# MSS_CTRL_MSS_CTRL register map
Vendor: Texas Instruments
Peripheral module from a debugger description file (folder AM263).
Registers are 32-bit, read-only, reset 0x0 unless marked. A register's access mark holds for its fields unless they carry their own. Offsets are as the file gives them; lines under a group give offsets from that group; [hi:lo] are bit positions; {n}, {i} and the like mark numbered series; 'fields as' and 'values as' point back to an identical list; <NAME> marks a mode.

## MSS_CTRL_MSS_CTRL (part 1 of 5)
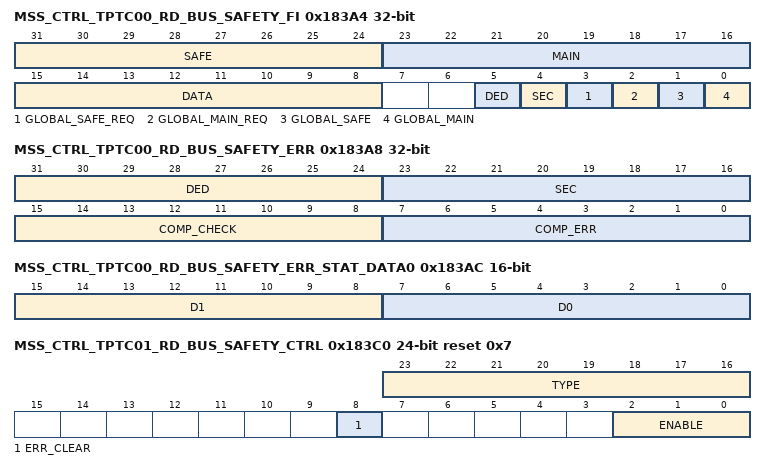
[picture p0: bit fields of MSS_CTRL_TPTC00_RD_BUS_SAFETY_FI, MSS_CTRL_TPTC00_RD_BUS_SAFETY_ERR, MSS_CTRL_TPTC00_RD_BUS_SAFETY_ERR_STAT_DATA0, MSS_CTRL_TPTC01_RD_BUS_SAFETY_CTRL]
0x183A4 MSS_CTRL_TPTC00_RD_BUS_SAFETY_FI rw
  [31:24] SAFE — Refer to AM602 Substem Microarch document for more details
  [23:16] MAIN — Refer to AM602 Substem Microarch document for more details
  [15:8] DATA — Refer to AM602 Substem Microarch document for more details
  [5] DED — Refer to AM602 Substem Microarch document for more details
  [4] SEC — Refer to AM602 Substem Microarch document for more details
  [3] GLOBAL_SAFE_REQ — Refer to AM602 Substem Microarch document for more details
  [2] GLOBAL_MAIN_REQ — Refer to AM602 Substem Microarch document for more details
  [1] GLOBAL_SAFE — Refer to AM602 Substem Microarch document for more details
  [0] GLOBAL_MAIN — Refer to AM602 Substem Microarch document for more details
0x183A8 MSS_CTRL_TPTC00_RD_BUS_SAFETY_ERR
  [31:24] DED — Refer to AM602 Substem Microarch document for more details
  [23:16] SEC — Refer to AM602 Substem Microarch document for more details
  [15:8] COMP_CHECK — Refer to AM602 Substem Microarch document for more details
  [7:0] COMP_ERR — Refer to AM602 Substem Microarch document for more details
0x183AC MSS_CTRL_TPTC00_RD_BUS_SAFETY_ERR_STAT_DATA0 16-bit
  [15:8] D1 — Refer to AM602 Substem Microarch document for more details
  [7:0] D0 — Refer to AM602 Substem Microarch document for more details
0x183B0 MSS_CTRL_TPTC00_RD_BUS_SAFETY_ERR_STAT_CMD
  [31:0] STAT — Refer to AM602 Substem Microarch document for more details
0x183B4 MSS_CTRL_TPTC00_RD_BUS_SAFETY_ERR_STAT_READ
  fields as MSS_CTRL_TPTC00_RD_BUS_SAFETY_ERR_STAT_CMD
0x183C0 MSS_CTRL_TPTC01_RD_BUS_SAFETY_CTRL 24-bit access per field reset 0x7
  [23:16] TYPE ro — Refer to AM602 Substem Microarch document for more details
  [8] ERR_CLEAR rw — Refer to AM602 Substem Microarch document for more details
  [2:0] ENABLE rw — Refer to AM602 Substem Microarch document for more details
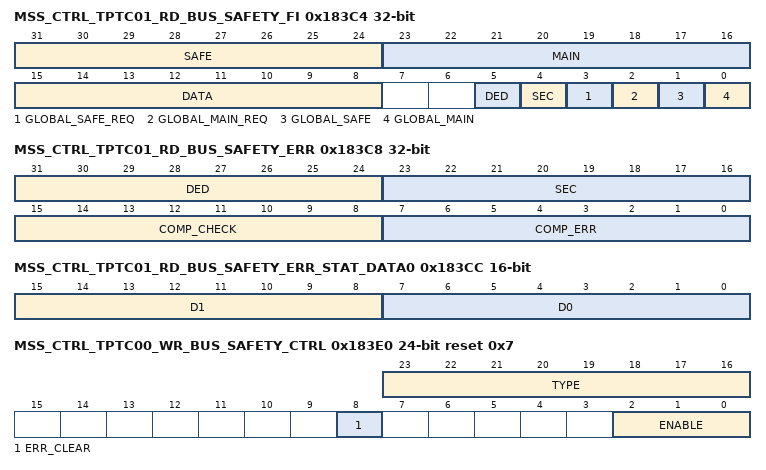
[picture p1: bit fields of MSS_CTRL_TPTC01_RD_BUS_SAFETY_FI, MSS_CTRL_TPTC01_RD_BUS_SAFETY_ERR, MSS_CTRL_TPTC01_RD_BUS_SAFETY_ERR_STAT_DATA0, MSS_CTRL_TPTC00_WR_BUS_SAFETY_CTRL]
0x183C4 MSS_CTRL_TPTC01_RD_BUS_SAFETY_FI rw
  fields as MSS_CTRL_TPTC00_RD_BUS_SAFETY_FI
0x183C8 MSS_CTRL_TPTC01_RD_BUS_SAFETY_ERR
  fields as MSS_CTRL_TPTC00_RD_BUS_SAFETY_ERR
0x183CC MSS_CTRL_TPTC01_RD_BUS_SAFETY_ERR_STAT_DATA0 16-bit
  fields as MSS_CTRL_TPTC00_RD_BUS_SAFETY_ERR_STAT_DATA0
0x183D0 MSS_CTRL_TPTC01_RD_BUS_SAFETY_ERR_STAT_CMD
  fields as MSS_CTRL_TPTC00_RD_BUS_SAFETY_ERR_STAT_CMD
0x183D4 MSS_CTRL_TPTC01_RD_BUS_SAFETY_ERR_STAT_READ
  fields as MSS_CTRL_TPTC00_RD_BUS_SAFETY_ERR_STAT_CMD
0x183E0 MSS_CTRL_TPTC00_WR_BUS_SAFETY_CTRL 24-bit access per field reset 0x7
  fields as MSS_CTRL_TPTC01_RD_BUS_SAFETY_CTRL
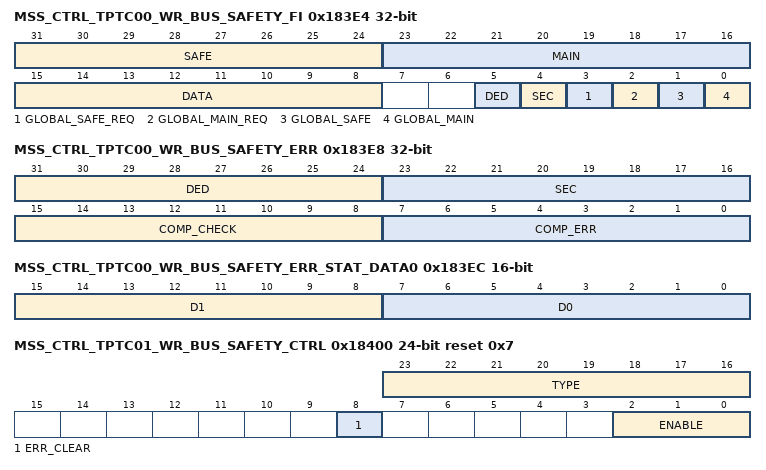
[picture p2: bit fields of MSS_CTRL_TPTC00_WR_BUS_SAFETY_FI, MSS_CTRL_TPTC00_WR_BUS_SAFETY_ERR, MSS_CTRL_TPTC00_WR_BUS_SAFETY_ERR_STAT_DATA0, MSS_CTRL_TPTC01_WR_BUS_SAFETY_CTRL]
0x183E4 MSS_CTRL_TPTC00_WR_BUS_SAFETY_FI rw
  fields as MSS_CTRL_TPTC00_RD_BUS_SAFETY_FI
0x183E8 MSS_CTRL_TPTC00_WR_BUS_SAFETY_ERR
  fields as MSS_CTRL_TPTC00_RD_BUS_SAFETY_ERR
0x183EC MSS_CTRL_TPTC00_WR_BUS_SAFETY_ERR_STAT_DATA0 16-bit
  fields as MSS_CTRL_TPTC00_RD_BUS_SAFETY_ERR_STAT_DATA0
0x183F0 MSS_CTRL_TPTC00_WR_BUS_SAFETY_ERR_STAT_CMD
  fields as MSS_CTRL_TPTC00_RD_BUS_SAFETY_ERR_STAT_CMD
0x183F4 MSS_CTRL_TPTC00_WR_BUS_SAFETY_ERR_STAT_WRITE
  fields as MSS_CTRL_TPTC00_RD_BUS_SAFETY_ERR_STAT_CMD
0x183F8 MSS_CTRL_TPTC00_WR_BUS_SAFETY_ERR_STAT_WRITERESP
  fields as MSS_CTRL_TPTC00_RD_BUS_SAFETY_ERR_STAT_CMD
0x18400 MSS_CTRL_TPTC01_WR_BUS_SAFETY_CTRL 24-bit access per field reset 0x7
  fields as MSS_CTRL_TPTC01_RD_BUS_SAFETY_CTRL
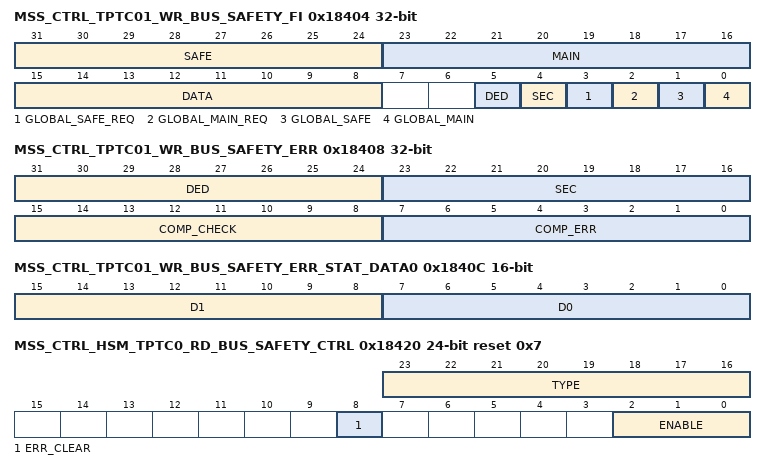
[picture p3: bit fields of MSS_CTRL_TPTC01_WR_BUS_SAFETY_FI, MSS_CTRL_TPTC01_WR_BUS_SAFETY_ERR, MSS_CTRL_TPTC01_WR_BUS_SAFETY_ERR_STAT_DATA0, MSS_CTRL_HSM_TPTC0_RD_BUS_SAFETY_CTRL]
0x18404 MSS_CTRL_TPTC01_WR_BUS_SAFETY_FI rw
  fields as MSS_CTRL_TPTC00_RD_BUS_SAFETY_FI
0x18408 MSS_CTRL_TPTC01_WR_BUS_SAFETY_ERR
  fields as MSS_CTRL_TPTC00_RD_BUS_SAFETY_ERR
0x1840C MSS_CTRL_TPTC01_WR_BUS_SAFETY_ERR_STAT_DATA0 16-bit
  fields as MSS_CTRL_TPTC00_RD_BUS_SAFETY_ERR_STAT_DATA0
0x18410 MSS_CTRL_TPTC01_WR_BUS_SAFETY_ERR_STAT_CMD
  fields as MSS_CTRL_TPTC00_RD_BUS_SAFETY_ERR_STAT_CMD
0x18414 MSS_CTRL_TPTC01_WR_BUS_SAFETY_ERR_STAT_WRITE
  fields as MSS_CTRL_TPTC00_RD_BUS_SAFETY_ERR_STAT_CMD
0x18418 MSS_CTRL_TPTC01_WR_BUS_SAFETY_ERR_STAT_WRITERESP
  fields as MSS_CTRL_TPTC00_RD_BUS_SAFETY_ERR_STAT_CMD
0x18420 MSS_CTRL_HSM_TPTC0_RD_BUS_SAFETY_CTRL 24-bit access per field reset 0x7
  fields as MSS_CTRL_TPTC01_RD_BUS_SAFETY_CTRL
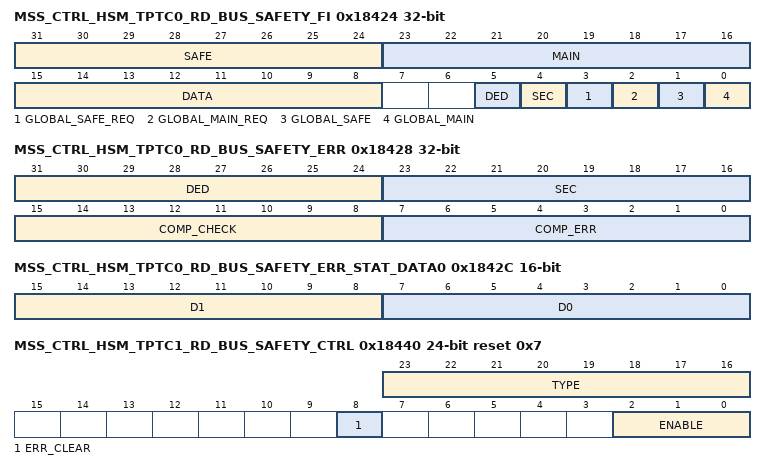
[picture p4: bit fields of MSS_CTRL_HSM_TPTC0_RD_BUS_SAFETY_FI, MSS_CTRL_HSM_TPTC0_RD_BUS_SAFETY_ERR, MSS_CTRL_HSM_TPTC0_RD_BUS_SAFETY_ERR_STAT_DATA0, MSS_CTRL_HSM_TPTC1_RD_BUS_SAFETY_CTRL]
0x18424 MSS_CTRL_HSM_TPTC0_RD_BUS_SAFETY_FI rw
  fields as MSS_CTRL_TPTC00_RD_BUS_SAFETY_FI
0x18428 MSS_CTRL_HSM_TPTC0_RD_BUS_SAFETY_ERR
  fields as MSS_CTRL_TPTC00_RD_BUS_SAFETY_ERR
0x1842C MSS_CTRL_HSM_TPTC0_RD_BUS_SAFETY_ERR_STAT_DATA0 16-bit
  fields as MSS_CTRL_TPTC00_RD_BUS_SAFETY_ERR_STAT_DATA0
0x18430 MSS_CTRL_HSM_TPTC0_RD_BUS_SAFETY_ERR_STAT_CMD
  fields as MSS_CTRL_TPTC00_RD_BUS_SAFETY_ERR_STAT_CMD
0x18434 MSS_CTRL_HSM_TPTC0_RD_BUS_SAFETY_ERR_STAT_READ
  fields as MSS_CTRL_TPTC00_RD_BUS_SAFETY_ERR_STAT_CMD
0x18440 MSS_CTRL_HSM_TPTC1_RD_BUS_SAFETY_CTRL 24-bit access per field reset 0x7
  fields as MSS_CTRL_TPTC01_RD_BUS_SAFETY_CTRL
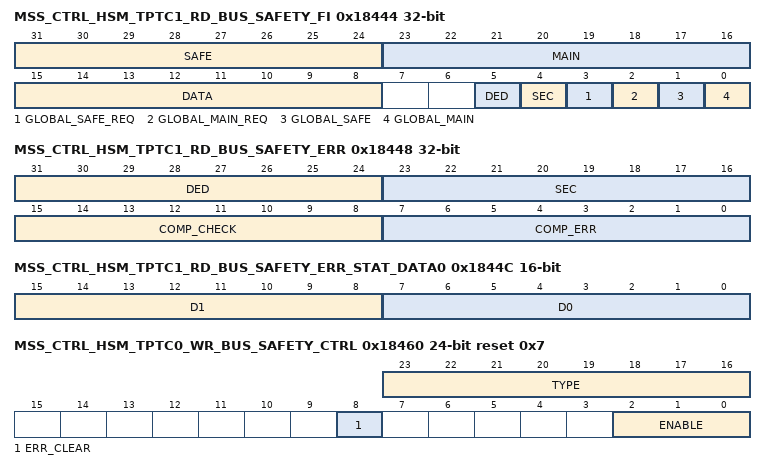
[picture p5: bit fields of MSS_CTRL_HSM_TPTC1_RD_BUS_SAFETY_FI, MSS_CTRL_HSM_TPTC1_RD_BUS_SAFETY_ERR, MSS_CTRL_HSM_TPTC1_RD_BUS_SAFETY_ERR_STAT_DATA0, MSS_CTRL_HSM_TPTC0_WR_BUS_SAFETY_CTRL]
0x18444 MSS_CTRL_HSM_TPTC1_RD_BUS_SAFETY_FI rw
  fields as MSS_CTRL_TPTC00_RD_BUS_SAFETY_FI
0x18448 MSS_CTRL_HSM_TPTC1_RD_BUS_SAFETY_ERR
  fields as MSS_CTRL_TPTC00_RD_BUS_SAFETY_ERR
0x1844C MSS_CTRL_HSM_TPTC1_RD_BUS_SAFETY_ERR_STAT_DATA0 16-bit
  fields as MSS_CTRL_TPTC00_RD_BUS_SAFETY_ERR_STAT_DATA0
0x18450 MSS_CTRL_HSM_TPTC1_RD_BUS_SAFETY_ERR_STAT_CMD
  fields as MSS_CTRL_TPTC00_RD_BUS_SAFETY_ERR_STAT_CMD
0x18454 MSS_CTRL_HSM_TPTC1_RD_BUS_SAFETY_ERR_STAT_READ
  fields as MSS_CTRL_TPTC00_RD_BUS_SAFETY_ERR_STAT_CMD
0x18460 MSS_CTRL_HSM_TPTC0_WR_BUS_SAFETY_CTRL 24-bit access per field reset 0x7
  fields as MSS_CTRL_TPTC01_RD_BUS_SAFETY_CTRL
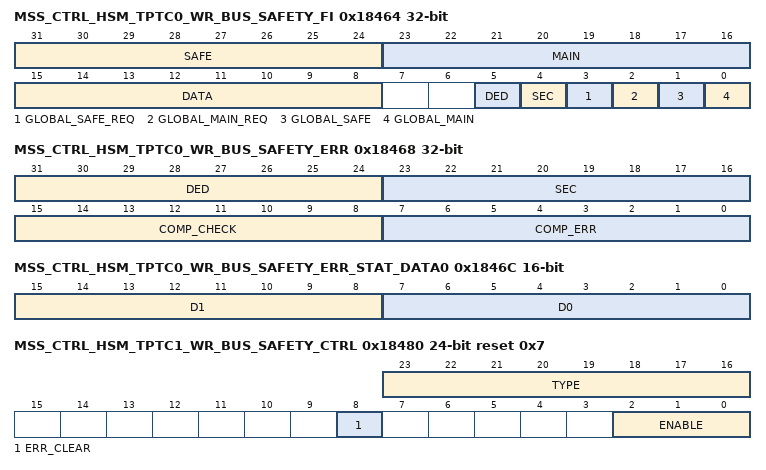
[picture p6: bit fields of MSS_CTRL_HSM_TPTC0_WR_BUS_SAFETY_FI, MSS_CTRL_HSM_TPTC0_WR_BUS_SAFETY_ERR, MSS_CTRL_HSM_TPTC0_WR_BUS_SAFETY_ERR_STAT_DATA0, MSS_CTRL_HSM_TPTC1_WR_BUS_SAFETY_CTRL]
0x18464 MSS_CTRL_HSM_TPTC0_WR_BUS_SAFETY_FI rw
  fields as MSS_CTRL_TPTC00_RD_BUS_SAFETY_FI
0x18468 MSS_CTRL_HSM_TPTC0_WR_BUS_SAFETY_ERR
  fields as MSS_CTRL_TPTC00_RD_BUS_SAFETY_ERR
0x1846C MSS_CTRL_HSM_TPTC0_WR_BUS_SAFETY_ERR_STAT_DATA0 16-bit
  fields as MSS_CTRL_TPTC00_RD_BUS_SAFETY_ERR_STAT_DATA0
0x18470 MSS_CTRL_HSM_TPTC0_WR_BUS_SAFETY_ERR_STAT_CMD
  fields as MSS_CTRL_TPTC00_RD_BUS_SAFETY_ERR_STAT_CMD
0x18474 MSS_CTRL_HSM_TPTC0_WR_BUS_SAFETY_ERR_STAT_WRITE
  fields as MSS_CTRL_TPTC00_RD_BUS_SAFETY_ERR_STAT_CMD
0x18478 MSS_CTRL_HSM_TPTC0_WR_BUS_SAFETY_ERR_STAT_WRITERESP
  fields as MSS_CTRL_TPTC00_RD_BUS_SAFETY_ERR_STAT_CMD
0x18480 MSS_CTRL_HSM_TPTC1_WR_BUS_SAFETY_CTRL 24-bit access per field reset 0x7
  fields as MSS_CTRL_TPTC01_RD_BUS_SAFETY_CTRL
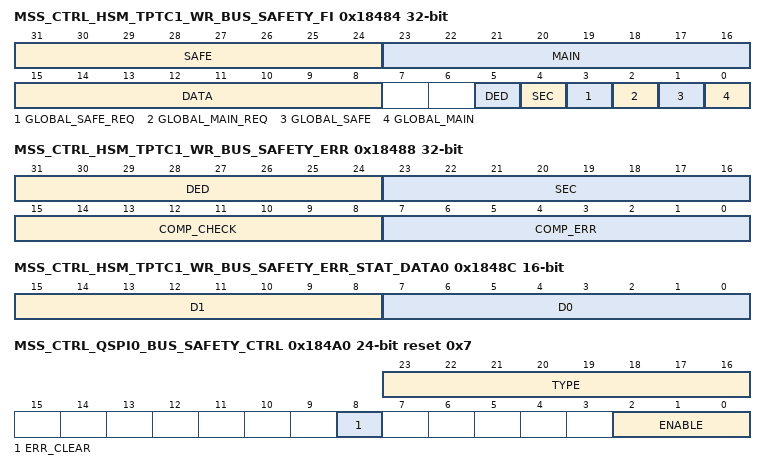
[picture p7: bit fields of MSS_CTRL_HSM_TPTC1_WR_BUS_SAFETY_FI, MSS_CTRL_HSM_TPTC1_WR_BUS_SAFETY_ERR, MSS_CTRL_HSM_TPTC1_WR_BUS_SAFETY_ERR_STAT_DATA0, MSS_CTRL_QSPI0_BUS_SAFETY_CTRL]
0x18484 MSS_CTRL_HSM_TPTC1_WR_BUS_SAFETY_FI rw
  fields as MSS_CTRL_TPTC00_RD_BUS_SAFETY_FI
0x18488 MSS_CTRL_HSM_TPTC1_WR_BUS_SAFETY_ERR
  fields as MSS_CTRL_TPTC00_RD_BUS_SAFETY_ERR
0x1848C MSS_CTRL_HSM_TPTC1_WR_BUS_SAFETY_ERR_STAT_DATA0 16-bit
  fields as MSS_CTRL_TPTC00_RD_BUS_SAFETY_ERR_STAT_DATA0
0x18490 MSS_CTRL_HSM_TPTC1_WR_BUS_SAFETY_ERR_STAT_CMD
  fields as MSS_CTRL_TPTC00_RD_BUS_SAFETY_ERR_STAT_CMD
0x18494 MSS_CTRL_HSM_TPTC1_WR_BUS_SAFETY_ERR_STAT_WRITE
  fields as MSS_CTRL_TPTC00_RD_BUS_SAFETY_ERR_STAT_CMD
0x18498 MSS_CTRL_HSM_TPTC1_WR_BUS_SAFETY_ERR_STAT_WRITERESP
  fields as MSS_CTRL_TPTC00_RD_BUS_SAFETY_ERR_STAT_CMD
0x184A0 MSS_CTRL_QSPI0_BUS_SAFETY_CTRL 24-bit access per field reset 0x7
  fields as MSS_CTRL_TPTC01_RD_BUS_SAFETY_CTRL
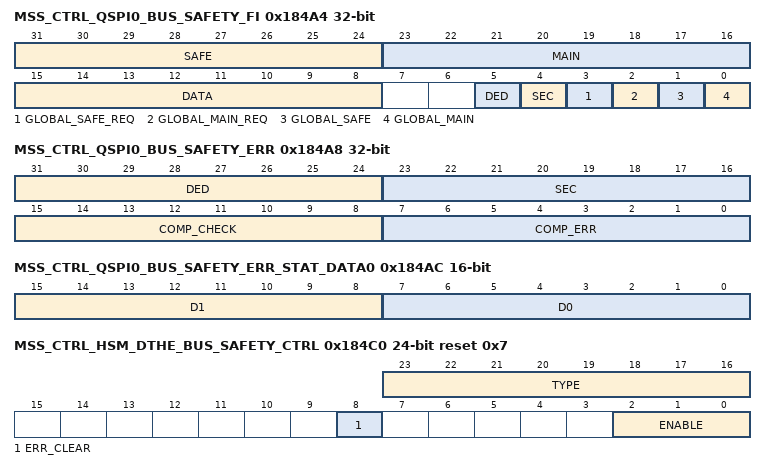
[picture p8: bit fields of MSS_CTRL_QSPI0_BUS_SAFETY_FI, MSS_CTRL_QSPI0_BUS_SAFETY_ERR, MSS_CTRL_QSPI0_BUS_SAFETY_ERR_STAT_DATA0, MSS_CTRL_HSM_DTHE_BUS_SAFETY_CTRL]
0x184A4 MSS_CTRL_QSPI0_BUS_SAFETY_FI rw
  fields as MSS_CTRL_TPTC00_RD_BUS_SAFETY_FI
0x184A8 MSS_CTRL_QSPI0_BUS_SAFETY_ERR
  fields as MSS_CTRL_TPTC00_RD_BUS_SAFETY_ERR
0x184AC MSS_CTRL_QSPI0_BUS_SAFETY_ERR_STAT_DATA0 16-bit
  fields as MSS_CTRL_TPTC00_RD_BUS_SAFETY_ERR_STAT_DATA0
0x184B0 MSS_CTRL_QSPI0_BUS_SAFETY_ERR_STAT_CMD
  fields as MSS_CTRL_TPTC00_RD_BUS_SAFETY_ERR_STAT_CMD
0x184B4 MSS_CTRL_QSPI0_BUS_SAFETY_ERR_STAT_WRITE
  fields as MSS_CTRL_TPTC00_RD_BUS_SAFETY_ERR_STAT_CMD
0x184B8 MSS_CTRL_QSPI0_BUS_SAFETY_ERR_STAT_READ
  fields as MSS_CTRL_TPTC00_RD_BUS_SAFETY_ERR_STAT_CMD
0x184BC MSS_CTRL_QSPI0_BUS_SAFETY_ERR_STAT_WRITERESP
  fields as MSS_CTRL_TPTC00_RD_BUS_SAFETY_ERR_STAT_CMD
0x184C0 MSS_CTRL_HSM_DTHE_BUS_SAFETY_CTRL 24-bit access per field reset 0x7
  fields as MSS_CTRL_TPTC01_RD_BUS_SAFETY_CTRL
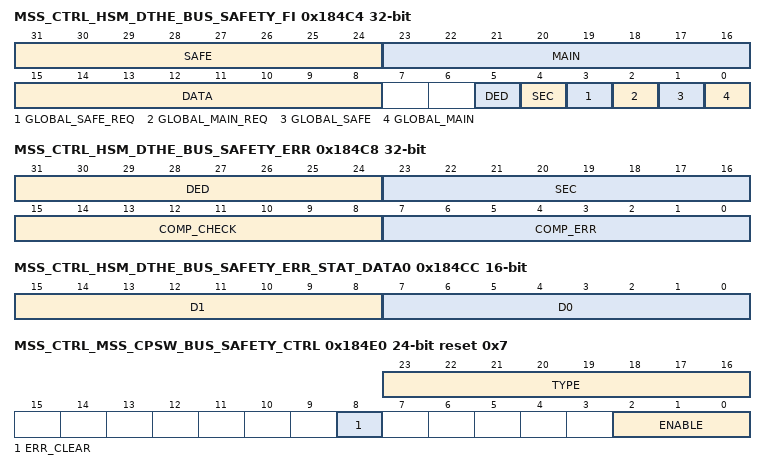
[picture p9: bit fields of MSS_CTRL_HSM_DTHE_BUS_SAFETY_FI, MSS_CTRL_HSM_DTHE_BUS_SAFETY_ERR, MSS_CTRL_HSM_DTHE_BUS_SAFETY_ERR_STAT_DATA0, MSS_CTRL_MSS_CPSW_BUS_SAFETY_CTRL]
0x184C4 MSS_CTRL_HSM_DTHE_BUS_SAFETY_FI rw
  fields as MSS_CTRL_TPTC00_RD_BUS_SAFETY_FI
0x184C8 MSS_CTRL_HSM_DTHE_BUS_SAFETY_ERR
  fields as MSS_CTRL_TPTC00_RD_BUS_SAFETY_ERR
0x184CC MSS_CTRL_HSM_DTHE_BUS_SAFETY_ERR_STAT_DATA0 16-bit
  fields as MSS_CTRL_TPTC00_RD_BUS_SAFETY_ERR_STAT_DATA0
0x184D0 MSS_CTRL_HSM_DTHE_BUS_SAFETY_ERR_STAT_CMD
  fields as MSS_CTRL_TPTC00_RD_BUS_SAFETY_ERR_STAT_CMD
0x184D4 MSS_CTRL_HSM_DTHE_BUS_SAFETY_ERR_STAT_WRITE
  fields as MSS_CTRL_TPTC00_RD_BUS_SAFETY_ERR_STAT_CMD
0x184D8 MSS_CTRL_HSM_DTHE_BUS_SAFETY_ERR_STAT_READ
  fields as MSS_CTRL_TPTC00_RD_BUS_SAFETY_ERR_STAT_CMD
0x184DC MSS_CTRL_HSM_DTHE_BUS_SAFETY_ERR_STAT_WRITERESP
  fields as MSS_CTRL_TPTC00_RD_BUS_SAFETY_ERR_STAT_CMD
0x184E0 MSS_CTRL_MSS_CPSW_BUS_SAFETY_CTRL 24-bit access per field reset 0x7
  fields as MSS_CTRL_TPTC01_RD_BUS_SAFETY_CTRL
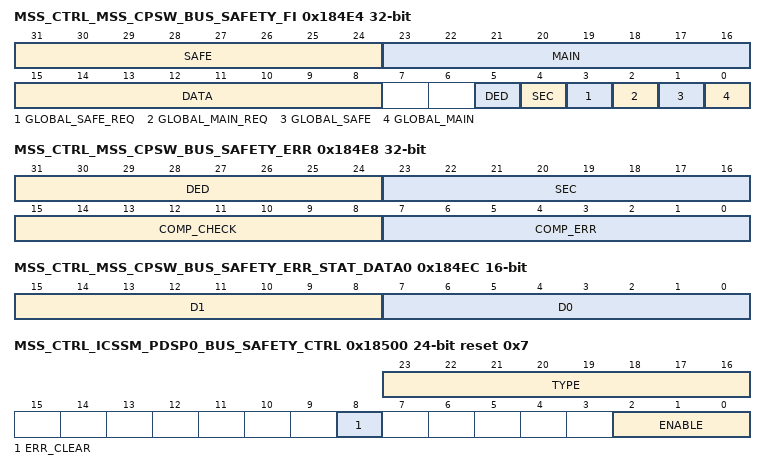
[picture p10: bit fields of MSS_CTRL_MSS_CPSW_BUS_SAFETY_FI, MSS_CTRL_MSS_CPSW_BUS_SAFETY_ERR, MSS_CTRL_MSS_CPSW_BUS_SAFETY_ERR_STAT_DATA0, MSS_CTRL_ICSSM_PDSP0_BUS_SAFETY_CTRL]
0x184E4 MSS_CTRL_MSS_CPSW_BUS_SAFETY_FI rw
  fields as MSS_CTRL_TPTC00_RD_BUS_SAFETY_FI
0x184E8 MSS_CTRL_MSS_CPSW_BUS_SAFETY_ERR
  fields as MSS_CTRL_TPTC00_RD_BUS_SAFETY_ERR
0x184EC MSS_CTRL_MSS_CPSW_BUS_SAFETY_ERR_STAT_DATA0 16-bit
  fields as MSS_CTRL_TPTC00_RD_BUS_SAFETY_ERR_STAT_DATA0
0x184F0 MSS_CTRL_MSS_CPSW_BUS_SAFETY_ERR_STAT_CMD
  fields as MSS_CTRL_TPTC00_RD_BUS_SAFETY_ERR_STAT_CMD
0x184F4 MSS_CTRL_MSS_CPSW_BUS_SAFETY_ERR_STAT_WRITE
  fields as MSS_CTRL_TPTC00_RD_BUS_SAFETY_ERR_STAT_CMD
0x184F8 MSS_CTRL_MSS_CPSW_BUS_SAFETY_ERR_STAT_READ
  fields as MSS_CTRL_TPTC00_RD_BUS_SAFETY_ERR_STAT_CMD
0x184FC MSS_CTRL_MSS_CPSW_BUS_SAFETY_ERR_STAT_WRITERESP
  fields as MSS_CTRL_TPTC00_RD_BUS_SAFETY_ERR_STAT_CMD
0x18500 MSS_CTRL_ICSSM_PDSP0_BUS_SAFETY_CTRL 24-bit access per field reset 0x7
  fields as MSS_CTRL_TPTC01_RD_BUS_SAFETY_CTRL
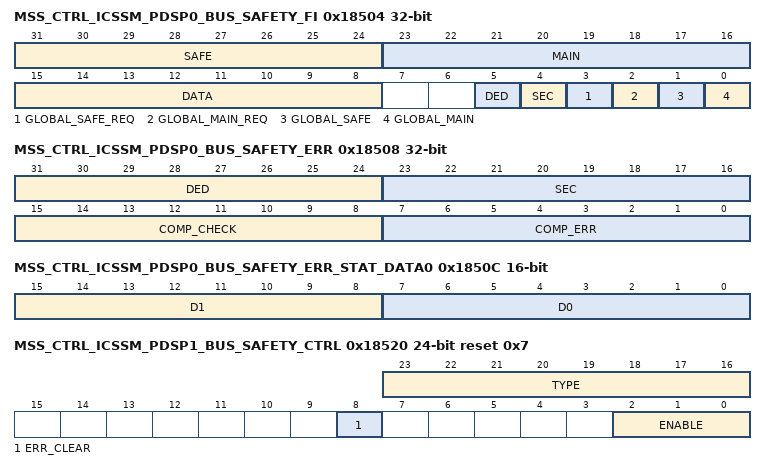
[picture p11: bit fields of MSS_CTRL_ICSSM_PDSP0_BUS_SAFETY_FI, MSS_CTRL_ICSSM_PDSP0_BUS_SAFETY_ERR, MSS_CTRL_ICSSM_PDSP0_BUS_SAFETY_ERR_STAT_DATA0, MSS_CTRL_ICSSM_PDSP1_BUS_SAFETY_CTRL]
0x18504 MSS_CTRL_ICSSM_PDSP0_BUS_SAFETY_FI rw
  fields as MSS_CTRL_TPTC00_RD_BUS_SAFETY_FI
0x18508 MSS_CTRL_ICSSM_PDSP0_BUS_SAFETY_ERR
  fields as MSS_CTRL_TPTC00_RD_BUS_SAFETY_ERR
0x1850C MSS_CTRL_ICSSM_PDSP0_BUS_SAFETY_ERR_STAT_DATA0 16-bit
  fields as MSS_CTRL_TPTC00_RD_BUS_SAFETY_ERR_STAT_DATA0
0x18510 MSS_CTRL_ICSSM_PDSP0_BUS_SAFETY_ERR_STAT_CMD
  fields as MSS_CTRL_TPTC00_RD_BUS_SAFETY_ERR_STAT_CMD
0x18514 MSS_CTRL_ICSSM_PDSP0_BUS_SAFETY_ERR_STAT_WRITE
  fields as MSS_CTRL_TPTC00_RD_BUS_SAFETY_ERR_STAT_CMD
0x18518 MSS_CTRL_ICSSM_PDSP0_BUS_SAFETY_ERR_STAT_READ
  fields as MSS_CTRL_TPTC00_RD_BUS_SAFETY_ERR_STAT_CMD
0x1851C MSS_CTRL_ICSSM_PDSP0_BUS_SAFETY_ERR_STAT_WRITERESP
  fields as MSS_CTRL_TPTC00_RD_BUS_SAFETY_ERR_STAT_CMD
0x18520 MSS_CTRL_ICSSM_PDSP1_BUS_SAFETY_CTRL 24-bit access per field reset 0x7
  fields as MSS_CTRL_TPTC01_RD_BUS_SAFETY_CTRL
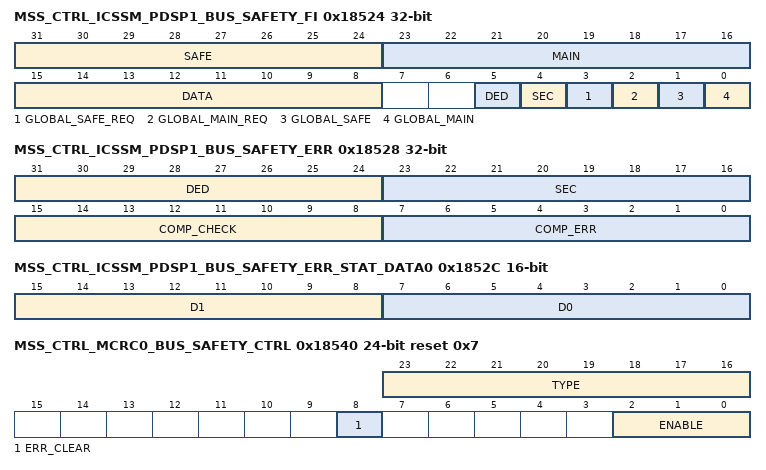
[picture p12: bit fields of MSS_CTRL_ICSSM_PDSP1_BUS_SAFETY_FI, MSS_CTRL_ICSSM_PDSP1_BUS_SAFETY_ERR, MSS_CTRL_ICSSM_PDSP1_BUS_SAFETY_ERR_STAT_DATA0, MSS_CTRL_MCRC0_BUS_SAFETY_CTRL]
0x18524 MSS_CTRL_ICSSM_PDSP1_BUS_SAFETY_FI rw
  fields as MSS_CTRL_TPTC00_RD_BUS_SAFETY_FI
0x18528 MSS_CTRL_ICSSM_PDSP1_BUS_SAFETY_ERR
  fields as MSS_CTRL_TPTC00_RD_BUS_SAFETY_ERR
0x1852C MSS_CTRL_ICSSM_PDSP1_BUS_SAFETY_ERR_STAT_DATA0 16-bit
  fields as MSS_CTRL_TPTC00_RD_BUS_SAFETY_ERR_STAT_DATA0
0x18530 MSS_CTRL_ICSSM_PDSP1_BUS_SAFETY_ERR_STAT_CMD
  fields as MSS_CTRL_TPTC00_RD_BUS_SAFETY_ERR_STAT_CMD
0x18534 MSS_CTRL_ICSSM_PDSP1_BUS_SAFETY_ERR_STAT_WRITE
  fields as MSS_CTRL_TPTC00_RD_BUS_SAFETY_ERR_STAT_CMD
0x18538 MSS_CTRL_ICSSM_PDSP1_BUS_SAFETY_ERR_STAT_READ
  fields as MSS_CTRL_TPTC00_RD_BUS_SAFETY_ERR_STAT_CMD
0x1853C MSS_CTRL_ICSSM_PDSP1_BUS_SAFETY_ERR_STAT_WRITERESP
  fields as MSS_CTRL_TPTC00_RD_BUS_SAFETY_ERR_STAT_CMD
0x18540 MSS_CTRL_MCRC0_BUS_SAFETY_CTRL 24-bit access per field reset 0x7
  fields as MSS_CTRL_TPTC01_RD_BUS_SAFETY_CTRL
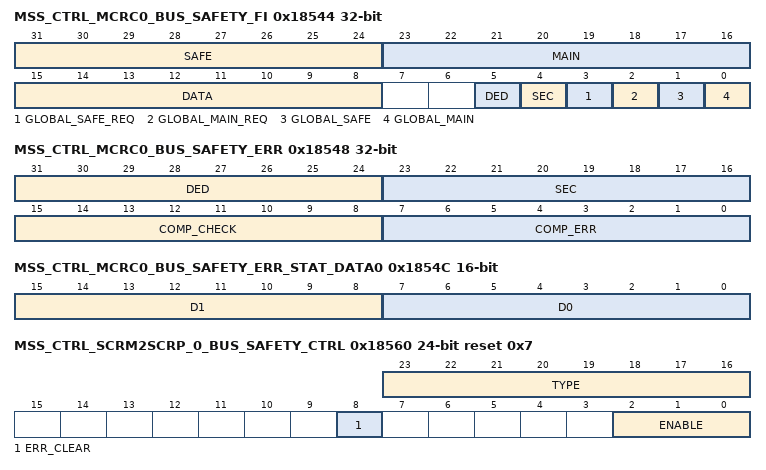
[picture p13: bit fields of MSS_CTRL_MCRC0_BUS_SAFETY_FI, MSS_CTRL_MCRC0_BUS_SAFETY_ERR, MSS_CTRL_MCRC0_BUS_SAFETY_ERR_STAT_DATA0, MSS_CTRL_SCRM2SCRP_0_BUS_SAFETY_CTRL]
0x18544 MSS_CTRL_MCRC0_BUS_SAFETY_FI rw
  fields as MSS_CTRL_TPTC00_RD_BUS_SAFETY_FI
0x18548 MSS_CTRL_MCRC0_BUS_SAFETY_ERR
  fields as MSS_CTRL_TPTC00_RD_BUS_SAFETY_ERR
0x1854C MSS_CTRL_MCRC0_BUS_SAFETY_ERR_STAT_DATA0 16-bit
  fields as MSS_CTRL_TPTC00_RD_BUS_SAFETY_ERR_STAT_DATA0
0x18550 MSS_CTRL_MCRC0_BUS_SAFETY_ERR_STAT_CMD
  fields as MSS_CTRL_TPTC00_RD_BUS_SAFETY_ERR_STAT_CMD
0x18554 MSS_CTRL_MCRC0_BUS_SAFETY_ERR_STAT_WRITE
  fields as MSS_CTRL_TPTC00_RD_BUS_SAFETY_ERR_STAT_CMD
0x18558 MSS_CTRL_MCRC0_BUS_SAFETY_ERR_STAT_READ
  fields as MSS_CTRL_TPTC00_RD_BUS_SAFETY_ERR_STAT_CMD
0x1855C MSS_CTRL_MCRC0_BUS_SAFETY_ERR_STAT_WRITERESP
  fields as MSS_CTRL_TPTC00_RD_BUS_SAFETY_ERR_STAT_CMD
0x18560 MSS_CTRL_SCRM2SCRP_0_BUS_SAFETY_CTRL 24-bit access per field reset 0x7
  fields as MSS_CTRL_TPTC01_RD_BUS_SAFETY_CTRL
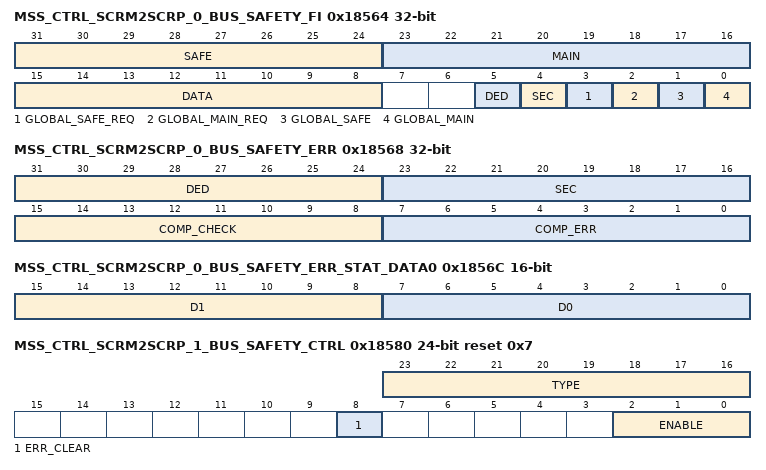
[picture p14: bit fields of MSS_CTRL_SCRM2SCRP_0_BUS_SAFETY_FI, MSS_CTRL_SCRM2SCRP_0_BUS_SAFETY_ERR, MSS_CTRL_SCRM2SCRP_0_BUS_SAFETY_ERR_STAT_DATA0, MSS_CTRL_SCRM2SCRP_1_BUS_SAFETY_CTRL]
0x18564 MSS_CTRL_SCRM2SCRP_0_BUS_SAFETY_FI rw
  fields as MSS_CTRL_TPTC00_RD_BUS_SAFETY_FI
0x18568 MSS_CTRL_SCRM2SCRP_0_BUS_SAFETY_ERR
  fields as MSS_CTRL_TPTC00_RD_BUS_SAFETY_ERR
0x1856C MSS_CTRL_SCRM2SCRP_0_BUS_SAFETY_ERR_STAT_DATA0 16-bit
  fields as MSS_CTRL_TPTC00_RD_BUS_SAFETY_ERR_STAT_DATA0
0x18570 MSS_CTRL_SCRM2SCRP_0_BUS_SAFETY_ERR_STAT_CMD
  fields as MSS_CTRL_TPTC00_RD_BUS_SAFETY_ERR_STAT_CMD
0x18574 MSS_CTRL_SCRM2SCRP_0_BUS_SAFETY_ERR_STAT_WRITE
  fields as MSS_CTRL_TPTC00_RD_BUS_SAFETY_ERR_STAT_CMD
0x18578 MSS_CTRL_SCRM2SCRP_0_BUS_SAFETY_ERR_STAT_READ
  fields as MSS_CTRL_TPTC00_RD_BUS_SAFETY_ERR_STAT_CMD
0x1857C MSS_CTRL_SCRM2SCRP_0_BUS_SAFETY_ERR_STAT_WRITERESP
  fields as MSS_CTRL_TPTC00_RD_BUS_SAFETY_ERR_STAT_CMD
0x18580 MSS_CTRL_SCRM2SCRP_1_BUS_SAFETY_CTRL 24-bit access per field reset 0x7
  fields as MSS_CTRL_TPTC01_RD_BUS_SAFETY_CTRL
0x18584 MSS_CTRL_SCRM2SCRP_1_BUS_SAFETY_FI rw
  fields as MSS_CTRL_TPTC00_RD_BUS_SAFETY_FI
0x18588 MSS_CTRL_SCRM2SCRP_1_BUS_SAFETY_ERR
  fields as MSS_CTRL_TPTC00_RD_BUS_SAFETY_ERR
0x1858C MSS_CTRL_SCRM2SCRP_1_BUS_SAFETY_ERR_STAT_DATA0 16-bit
  fields as MSS_CTRL_TPTC00_RD_BUS_SAFETY_ERR_STAT_DATA0
0x18590 MSS_CTRL_SCRM2SCRP_1_BUS_SAFETY_ERR_STAT_CMD
  fields as MSS_CTRL_TPTC00_RD_BUS_SAFETY_ERR_STAT_CMD
0x18594 MSS_CTRL_SCRM2SCRP_1_BUS_SAFETY_ERR_STAT_WRITE
  fields as MSS_CTRL_TPTC00_RD_BUS_SAFETY_ERR_STAT_CMD
0x18598 MSS_CTRL_SCRM2SCRP_1_BUS_SAFETY_ERR_STAT_READ
  fields as MSS_CTRL_TPTC00_RD_BUS_SAFETY_ERR_STAT_CMD
0x1859C MSS_CTRL_SCRM2SCRP_1_BUS_SAFETY_ERR_STAT_WRITERESP
  fields as MSS_CTRL_TPTC00_RD_BUS_SAFETY_ERR_STAT_CMD
0x185A0 MSS_CTRL_HSM_M_BUS_SAFETY_CTRL 24-bit access per field reset 0x7
  fields as MSS_CTRL_TPTC01_RD_BUS_SAFETY_CTRL
0x185A4 MSS_CTRL_HSM_M_BUS_SAFETY_FI rw
  fields as MSS_CTRL_TPTC00_RD_BUS_SAFETY_FI
0x185A8 MSS_CTRL_HSM_M_BUS_SAFETY_ERR
  fields as MSS_CTRL_TPTC00_RD_BUS_SAFETY_ERR
0x185AC MSS_CTRL_HSM_M_BUS_SAFETY_ERR_STAT_DATA0 16-bit
  fields as MSS_CTRL_TPTC00_RD_BUS_SAFETY_ERR_STAT_DATA0
0x185B0 MSS_CTRL_HSM_M_BUS_SAFETY_ERR_STAT_CMD
  fields as MSS_CTRL_TPTC00_RD_BUS_SAFETY_ERR_STAT_CMD
0x185B4 MSS_CTRL_HSM_M_BUS_SAFETY_ERR_STAT_WRITE
  fields as MSS_CTRL_TPTC00_RD_BUS_SAFETY_ERR_STAT_CMD
0x185B8 MSS_CTRL_HSM_M_BUS_SAFETY_ERR_STAT_READ
  fields as MSS_CTRL_TPTC00_RD_BUS_SAFETY_ERR_STAT_CMD
0x185BC MSS_CTRL_HSM_M_BUS_SAFETY_ERR_STAT_WRITERESP
  fields as MSS_CTRL_TPTC00_RD_BUS_SAFETY_ERR_STAT_CMD
0x185C0 MSS_CTRL_HSM_S_BUS_SAFETY_CTRL 24-bit access per field reset 0x7
  fields as MSS_CTRL_TPTC01_RD_BUS_SAFETY_CTRL
0x185C4 MSS_CTRL_HSM_S_BUS_SAFETY_FI rw
  fields as MSS_CTRL_TPTC00_RD_BUS_SAFETY_FI
0x185C8 MSS_CTRL_HSM_S_BUS_SAFETY_ERR
  fields as MSS_CTRL_TPTC00_RD_BUS_SAFETY_ERR
0x185CC MSS_CTRL_HSM_S_BUS_SAFETY_ERR_STAT_DATA0 16-bit
  fields as MSS_CTRL_TPTC00_RD_BUS_SAFETY_ERR_STAT_DATA0
0x185D0 MSS_CTRL_HSM_S_BUS_SAFETY_ERR_STAT_CMD
  fields as MSS_CTRL_TPTC00_RD_BUS_SAFETY_ERR_STAT_CMD
0x185D4 MSS_CTRL_HSM_S_BUS_SAFETY_ERR_STAT_WRITE
  fields as MSS_CTRL_TPTC00_RD_BUS_SAFETY_ERR_STAT_CMD
0x185D8 MSS_CTRL_HSM_S_BUS_SAFETY_ERR_STAT_READ
  fields as MSS_CTRL_TPTC00_RD_BUS_SAFETY_ERR_STAT_CMD
0x185DC MSS_CTRL_HSM_S_BUS_SAFETY_ERR_STAT_WRITERESP
  fields as MSS_CTRL_TPTC00_RD_BUS_SAFETY_ERR_STAT_CMD
0x185E0 MSS_CTRL_ICSSM_S_BUS_SAFETY_CTRL 24-bit access per field reset 0x7
  fields as MSS_CTRL_TPTC01_RD_BUS_SAFETY_CTRL
0x185E4 MSS_CTRL_ICSSM_S_BUS_SAFETY_FI rw
  fields as MSS_CTRL_TPTC00_RD_BUS_SAFETY_FI
0x185E8 MSS_CTRL_ICSSM_S_BUS_SAFETY_ERR
  fields as MSS_CTRL_TPTC00_RD_BUS_SAFETY_ERR
0x185EC MSS_CTRL_ICSSM_S_BUS_SAFETY_ERR_STAT_DATA0 16-bit
  fields as MSS_CTRL_TPTC00_RD_BUS_SAFETY_ERR_STAT_DATA0
0x185F0 MSS_CTRL_ICSSM_S_BUS_SAFETY_ERR_STAT_CMD
  fields as MSS_CTRL_TPTC00_RD_BUS_SAFETY_ERR_STAT_CMD
0x185F4 MSS_CTRL_ICSSM_S_BUS_SAFETY_ERR_STAT_WRITE
  fields as MSS_CTRL_TPTC00_RD_BUS_SAFETY_ERR_STAT_CMD
0x185F8 MSS_CTRL_ICSSM_S_BUS_SAFETY_ERR_STAT_READ
  fields as MSS_CTRL_TPTC00_RD_BUS_SAFETY_ERR_STAT_CMD
0x185FC MSS_CTRL_ICSSM_S_BUS_SAFETY_ERR_STAT_WRITERESP
  fields as MSS_CTRL_TPTC00_RD_BUS_SAFETY_ERR_STAT_CMD
0x18600 MSS_CTRL_DAP_BUS_SAFETY_CTRL 24-bit access per field reset 0x7
  fields as MSS_CTRL_TPTC01_RD_BUS_SAFETY_CTRL
0x18604 MSS_CTRL_DAP_BUS_SAFETY_FI rw
  fields as MSS_CTRL_TPTC00_RD_BUS_SAFETY_FI
0x18608 MSS_CTRL_DAP_BUS_SAFETY_ERR
  fields as MSS_CTRL_TPTC00_RD_BUS_SAFETY_ERR
0x1860C MSS_CTRL_DAP_BUS_SAFETY_ERR_STAT_DATA0 16-bit
  fields as MSS_CTRL_TPTC00_RD_BUS_SAFETY_ERR_STAT_DATA0
0x18610 MSS_CTRL_DAP_BUS_SAFETY_ERR_STAT_CMD
  fields as MSS_CTRL_TPTC00_RD_BUS_SAFETY_ERR_STAT_CMD
0x18614 MSS_CTRL_DAP_BUS_SAFETY_ERR_STAT_WRITE
  fields as MSS_CTRL_TPTC00_RD_BUS_SAFETY_ERR_STAT_CMD
0x18618 MSS_CTRL_DAP_BUS_SAFETY_ERR_STAT_READ
  fields as MSS_CTRL_TPTC00_RD_BUS_SAFETY_ERR_STAT_CMD
0x1861C MSS_CTRL_DAP_BUS_SAFETY_ERR_STAT_WRITERESP
  fields as MSS_CTRL_TPTC00_RD_BUS_SAFETY_ERR_STAT_CMD
{0x18620+0x20*i} MSS_CTRL_L2OCRAM_BANK{i}_BUS_SAFETY_CTRL 24-bit access per field reset 0x7 (i=0..3)
  fields as MSS_CTRL_TPTC01_RD_BUS_SAFETY_CTRL
{0x18624+0x20*i} MSS_CTRL_L2OCRAM_BANK{i}_BUS_SAFETY_FI rw (i=0..3)
  fields as MSS_CTRL_TPTC00_RD_BUS_SAFETY_FI
{0x18628+0x20*i} MSS_CTRL_L2OCRAM_BANK{i}_BUS_SAFETY_ERR (i=0..3)
  fields as MSS_CTRL_TPTC00_RD_BUS_SAFETY_ERR
{0x1862C+0x20*i} MSS_CTRL_L2OCRAM_BANK{i}_BUS_SAFETY_ERR_STAT_DATA0 16-bit (i=0..3)
  fields as MSS_CTRL_TPTC00_RD_BUS_SAFETY_ERR_STAT_DATA0
{0x18630+0x20*i} MSS_CTRL_L2OCRAM_BANK{i}_BUS_SAFETY_ERR_STAT_CMD (i=0..3)
  fields as MSS_CTRL_TPTC00_RD_BUS_SAFETY_ERR_STAT_CMD
{0x18634+0x20*i} MSS_CTRL_L2OCRAM_BANK{i}_BUS_SAFETY_ERR_STAT_WRITE (i=0..3)
  fields as MSS_CTRL_TPTC00_RD_BUS_SAFETY_ERR_STAT_CMD
{0x18638+0x20*i} MSS_CTRL_L2OCRAM_BANK{i}_BUS_SAFETY_ERR_STAT_READ (i=0..3)
  fields as MSS_CTRL_TPTC00_RD_BUS_SAFETY_ERR_STAT_CMD
{0x1863C+0x20*i} MSS_CTRL_L2OCRAM_BANK{i}_BUS_SAFETY_ERR_STAT_WRITERESP (i=0..3)
  fields as MSS_CTRL_TPTC00_RD_BUS_SAFETY_ERR_STAT_CMD
0x186A0 MSS_CTRL_MBOX_SRAM_BUS_SAFETY_CTRL 24-bit access per field reset 0x7
  fields as MSS_CTRL_TPTC01_RD_BUS_SAFETY_CTRL
0x186A4 MSS_CTRL_MBOX_SRAM_BUS_SAFETY_FI rw
  fields as MSS_CTRL_TPTC00_RD_BUS_SAFETY_FI
0x186A8 MSS_CTRL_MBOX_SRAM_BUS_SAFETY_ERR
  fields as MSS_CTRL_TPTC00_RD_BUS_SAFETY_ERR
0x186AC MSS_CTRL_MBOX_SRAM_BUS_SAFETY_ERR_STAT_DATA0 16-bit
  fields as MSS_CTRL_TPTC00_RD_BUS_SAFETY_ERR_STAT_DATA0
0x186B0 MSS_CTRL_MBOX_SRAM_BUS_SAFETY_ERR_STAT_CMD
  fields as MSS_CTRL_TPTC00_RD_BUS_SAFETY_ERR_STAT_CMD
0x186B4 MSS_CTRL_MBOX_SRAM_BUS_SAFETY_ERR_STAT_WRITE
  fields as MSS_CTRL_TPTC00_RD_BUS_SAFETY_ERR_STAT_CMD
0x186B8 MSS_CTRL_MBOX_SRAM_BUS_SAFETY_ERR_STAT_READ
  fields as MSS_CTRL_TPTC00_RD_BUS_SAFETY_ERR_STAT_CMD
0x186BC MSS_CTRL_MBOX_SRAM_BUS_SAFETY_ERR_STAT_WRITERESP
  fields as MSS_CTRL_TPTC00_RD_BUS_SAFETY_ERR_STAT_CMD
0x186C0 MSS_CTRL_STM_STIM_BUS_SAFETY_CTRL 24-bit access per field reset 0x7
  fields as MSS_CTRL_TPTC01_RD_BUS_SAFETY_CTRL
0x186C4 MSS_CTRL_STM_STIM_BUS_SAFETY_FI rw
  fields as MSS_CTRL_TPTC00_RD_BUS_SAFETY_FI
0x186C8 MSS_CTRL_STM_STIM_BUS_SAFETY_ERR
  fields as MSS_CTRL_TPTC00_RD_BUS_SAFETY_ERR
0x186CC MSS_CTRL_STM_STIM_BUS_SAFETY_ERR_STAT_DATA0 16-bit
  fields as MSS_CTRL_TPTC00_RD_BUS_SAFETY_ERR_STAT_DATA0
0x186D0 MSS_CTRL_STM_STIM_BUS_SAFETY_ERR_STAT_CMD
  fields as MSS_CTRL_TPTC00_RD_BUS_SAFETY_ERR_STAT_CMD
0x186D4 MSS_CTRL_STM_STIM_BUS_SAFETY_ERR_STAT_WRITE
  fields as MSS_CTRL_TPTC00_RD_BUS_SAFETY_ERR_STAT_CMD
0x186D8 MSS_CTRL_STM_STIM_BUS_SAFETY_ERR_STAT_READ
  fields as MSS_CTRL_TPTC00_RD_BUS_SAFETY_ERR_STAT_CMD
0x186DC MSS_CTRL_STM_STIM_BUS_SAFETY_ERR_STAT_WRITERESP
  fields as MSS_CTRL_TPTC00_RD_BUS_SAFETY_ERR_STAT_CMD
0x186E0 MSS_CTRL_MMC0_BUS_SAFETY_CTRL 24-bit access per field reset 0x7
  fields as MSS_CTRL_TPTC01_RD_BUS_SAFETY_CTRL
0x186E4 MSS_CTRL_MMC0_BUS_SAFETY_FI rw
  fields as MSS_CTRL_TPTC00_RD_BUS_SAFETY_FI
0x186E8 MSS_CTRL_MMC0_BUS_SAFETY_ERR
  fields as MSS_CTRL_TPTC00_RD_BUS_SAFETY_ERR
0x186EC MSS_CTRL_MMC0_BUS_SAFETY_ERR_STAT_DATA0 16-bit
  fields as MSS_CTRL_TPTC00_RD_BUS_SAFETY_ERR_STAT_DATA0
0x186F0 MSS_CTRL_MMC0_BUS_SAFETY_ERR_STAT_CMD
  fields as MSS_CTRL_TPTC00_RD_BUS_SAFETY_ERR_STAT_CMD
0x186F4 MSS_CTRL_MMC0_BUS_SAFETY_ERR_STAT_WRITE
  fields as MSS_CTRL_TPTC00_RD_BUS_SAFETY_ERR_STAT_CMD
0x186F8 MSS_CTRL_MMC0_BUS_SAFETY_ERR_STAT_READ
  fields as MSS_CTRL_TPTC00_RD_BUS_SAFETY_ERR_STAT_CMD
0x186FC MSS_CTRL_MMC0_BUS_SAFETY_ERR_STAT_WRITERESP
  fields as MSS_CTRL_TPTC00_RD_BUS_SAFETY_ERR_STAT_CMD
0x18700 MSS_CTRL_GPMC0_BUS_SAFETY_CTRL 24-bit access per field reset 0x7
  fields as MSS_CTRL_TPTC01_RD_BUS_SAFETY_CTRL
0x18704 MSS_CTRL_GPMC0_BUS_SAFETY_FI rw
  fields as MSS_CTRL_TPTC00_RD_BUS_SAFETY_FI
0x18708 MSS_CTRL_GPMC0_BUS_SAFETY_ERR
  fields as MSS_CTRL_TPTC00_RD_BUS_SAFETY_ERR
0x1870C MSS_CTRL_GPMC0_BUS_SAFETY_ERR_STAT_DATA0 16-bit
  fields as MSS_CTRL_TPTC00_RD_BUS_SAFETY_ERR_STAT_DATA0
0x18710 MSS_CTRL_GPMC0_BUS_SAFETY_ERR_STAT_CMD
  fields as MSS_CTRL_TPTC00_RD_BUS_SAFETY_ERR_STAT_CMD
0x18714 MSS_CTRL_GPMC0_BUS_SAFETY_ERR_STAT_WRITE
  fields as MSS_CTRL_TPTC00_RD_BUS_SAFETY_ERR_STAT_CMD
0x18718 MSS_CTRL_GPMC0_BUS_SAFETY_ERR_STAT_READ
  fields as MSS_CTRL_TPTC00_RD_BUS_SAFETY_ERR_STAT_CMD
0x1871C MSS_CTRL_GPMC0_BUS_SAFETY_ERR_STAT_WRITERESP
  fields as MSS_CTRL_TPTC00_RD_BUS_SAFETY_ERR_STAT_CMD
0x18720 MSS_CTRL_MAIN_VBUSP_BUS_SAFETY_CTRL 24-bit access per field reset 0x7
  fields as MSS_CTRL_TPTC01_RD_BUS_SAFETY_CTRL
0x18724 MSS_CTRL_MAIN_VBUSP_BUS_SAFETY_FI rw
  fields as MSS_CTRL_TPTC00_RD_BUS_SAFETY_FI
0x18728 MSS_CTRL_MAIN_VBUSP_BUS_SAFETY_ERR
  fields as MSS_CTRL_TPTC00_RD_BUS_SAFETY_ERR
0x1872C MSS_CTRL_MAIN_VBUSP_BUS_SAFETY_ERR_STAT_DATA0 16-bit
  fields as MSS_CTRL_TPTC00_RD_BUS_SAFETY_ERR_STAT_DATA0
0x18730 MSS_CTRL_MAIN_VBUSP_BUS_SAFETY_ERR_STAT_CMD
  fields as MSS_CTRL_TPTC00_RD_BUS_SAFETY_ERR_STAT_CMD
0x18734 MSS_CTRL_MAIN_VBUSP_BUS_SAFETY_ERR_STAT_WRITE
  fields as MSS_CTRL_TPTC00_RD_BUS_SAFETY_ERR_STAT_CMD
0x18738 MSS_CTRL_MAIN_VBUSP_BUS_SAFETY_ERR_STAT_READ
  fields as MSS_CTRL_TPTC00_RD_BUS_SAFETY_ERR_STAT_CMD
0x1873C MSS_CTRL_MAIN_VBUSP_BUS_SAFETY_ERR_STAT_WRITERESP
  fields as MSS_CTRL_TPTC00_RD_BUS_SAFETY_ERR_STAT_CMD
0x18740 MSS_CTRL_R5SS0_CORE0_AHB_BUS_SAFETY_CTRL 24-bit access per field reset 0x7
  fields as MSS_CTRL_TPTC01_RD_BUS_SAFETY_CTRL
0x18744 MSS_CTRL_R5SS0_CORE0_AHB_BUS_SAFETY_FI rw
  fields as MSS_CTRL_TPTC00_RD_BUS_SAFETY_FI
0x18748 MSS_CTRL_R5SS0_CORE0_AHB_BUS_SAFETY_ERR
  fields as MSS_CTRL_TPTC00_RD_BUS_SAFETY_ERR
0x1874C MSS_CTRL_R5SS0_CORE0_AHB_BUS_SAFETY_ERR_STAT_DATA0 16-bit
  fields as MSS_CTRL_TPTC00_RD_BUS_SAFETY_ERR_STAT_DATA0
0x18750 MSS_CTRL_R5SS0_CORE0_AHB_BUS_SAFETY_ERR_STAT_CMD
  fields as MSS_CTRL_TPTC00_RD_BUS_SAFETY_ERR_STAT_CMD
0x18754 MSS_CTRL_R5SS0_CORE0_AHB_BUS_SAFETY_ERR_STAT_WRITE
  fields as MSS_CTRL_TPTC00_RD_BUS_SAFETY_ERR_STAT_CMD
0x18758 MSS_CTRL_R5SS0_CORE0_AHB_BUS_SAFETY_ERR_STAT_READ
  fields as MSS_CTRL_TPTC00_RD_BUS_SAFETY_ERR_STAT_CMD
0x1875C MSS_CTRL_R5SS0_CORE0_AHB_BUS_SAFETY_ERR_STAT_WRITERESP
  fields as MSS_CTRL_TPTC00_RD_BUS_SAFETY_ERR_STAT_CMD
0x18760 MSS_CTRL_R5SS0_CORE1_AHB_BUS_SAFETY_CTRL 24-bit access per field reset 0x7
  fields as MSS_CTRL_TPTC01_RD_BUS_SAFETY_CTRL
0x18764 MSS_CTRL_R5SS0_CORE1_AHB_BUS_SAFETY_FI rw
  fields as MSS_CTRL_TPTC00_RD_BUS_SAFETY_FI
0x18768 MSS_CTRL_R5SS0_CORE1_AHB_BUS_SAFETY_ERR
  fields as MSS_CTRL_TPTC00_RD_BUS_SAFETY_ERR
0x1876C MSS_CTRL_R5SS0_CORE1_AHB_BUS_SAFETY_ERR_STAT_DATA0 16-bit
  fields as MSS_CTRL_TPTC00_RD_BUS_SAFETY_ERR_STAT_DATA0
0x18770 MSS_CTRL_R5SS0_CORE1_AHB_BUS_SAFETY_ERR_STAT_CMD
  fields as MSS_CTRL_TPTC00_RD_BUS_SAFETY_ERR_STAT_CMD
0x18774 MSS_CTRL_R5SS0_CORE1_AHB_BUS_SAFETY_ERR_STAT_WRITE
  fields as MSS_CTRL_TPTC00_RD_BUS_SAFETY_ERR_STAT_CMD
0x18778 MSS_CTRL_R5SS0_CORE1_AHB_BUS_SAFETY_ERR_STAT_READ
  fields as MSS_CTRL_TPTC00_RD_BUS_SAFETY_ERR_STAT_CMD
0x1877C MSS_CTRL_R5SS0_CORE1_AHB_BUS_SAFETY_ERR_STAT_WRITERESP
  fields as MSS_CTRL_TPTC00_RD_BUS_SAFETY_ERR_STAT_CMD
0x18780 MSS_CTRL_R5SS1_CORE0_AHB_BUS_SAFETY_CTRL 24-bit access per field reset 0x7
  fields as MSS_CTRL_TPTC01_RD_BUS_SAFETY_CTRL
0x18784 MSS_CTRL_R5SS1_CORE0_AHB_BUS_SAFETY_FI rw
  fields as MSS_CTRL_TPTC00_RD_BUS_SAFETY_FI
0x18788 MSS_CTRL_R5SS1_CORE0_AHB_BUS_SAFETY_ERR
  fields as MSS_CTRL_TPTC00_RD_BUS_SAFETY_ERR
0x1878C MSS_CTRL_R5SS1_CORE0_AHB_BUS_SAFETY_ERR_STAT_DATA0 16-bit
  fields as MSS_CTRL_TPTC00_RD_BUS_SAFETY_ERR_STAT_DATA0
0x18790 MSS_CTRL_R5SS1_CORE0_AHB_BUS_SAFETY_ERR_STAT_CMD
  fields as MSS_CTRL_TPTC00_RD_BUS_SAFETY_ERR_STAT_CMD
0x18794 MSS_CTRL_R5SS1_CORE0_AHB_BUS_SAFETY_ERR_STAT_WRITE
  fields as MSS_CTRL_TPTC00_RD_BUS_SAFETY_ERR_STAT_CMD
0x18798 MSS_CTRL_R5SS1_CORE0_AHB_BUS_SAFETY_ERR_STAT_READ
  fields as MSS_CTRL_TPTC00_RD_BUS_SAFETY_ERR_STAT_CMD
0x1879C MSS_CTRL_R5SS1_CORE0_AHB_BUS_SAFETY_ERR_STAT_WRITERESP
  fields as MSS_CTRL_TPTC00_RD_BUS_SAFETY_ERR_STAT_CMD
0x187A0 MSS_CTRL_R5SS1_CORE1_AHB_BUS_SAFETY_CTRL 24-bit access per field reset 0x7
  fields as MSS_CTRL_TPTC01_RD_BUS_SAFETY_CTRL
0x187A4 MSS_CTRL_R5SS1_CORE1_AHB_BUS_SAFETY_FI rw
  fields as MSS_CTRL_TPTC00_RD_BUS_SAFETY_FI
0x187A8 MSS_CTRL_R5SS1_CORE1_AHB_BUS_SAFETY_ERR
  fields as MSS_CTRL_TPTC00_RD_BUS_SAFETY_ERR
0x187AC MSS_CTRL_R5SS1_CORE1_AHB_BUS_SAFETY_ERR_STAT_DATA0 16-bit
  fields as MSS_CTRL_TPTC00_RD_BUS_SAFETY_ERR_STAT_DATA0
0x187B0 MSS_CTRL_R5SS1_CORE1_AHB_BUS_SAFETY_ERR_STAT_CMD
  fields as MSS_CTRL_TPTC00_RD_BUS_SAFETY_ERR_STAT_CMD
0x187B4 MSS_CTRL_R5SS1_CORE1_AHB_BUS_SAFETY_ERR_STAT_WRITE
  fields as MSS_CTRL_TPTC00_RD_BUS_SAFETY_ERR_STAT_CMD
0x187B8 MSS_CTRL_R5SS1_CORE1_AHB_BUS_SAFETY_ERR_STAT_READ
  fields as MSS_CTRL_TPTC00_RD_BUS_SAFETY_ERR_STAT_CMD
0x187BC MSS_CTRL_R5SS1_CORE1_AHB_BUS_SAFETY_ERR_STAT_WRITERESP
  fields as MSS_CTRL_TPTC00_RD_BUS_SAFETY_ERR_STAT_CMD
0x187C0 MSS_CTRL_PERI_VBUSP_BUS_SAFETY_CTRL 24-bit access per field reset 0x7
  fields as MSS_CTRL_TPTC01_RD_BUS_SAFETY_CTRL
0x187C4 MSS_CTRL_PERI_VBUSP_BUS_SAFETY_FI rw
  fields as MSS_CTRL_TPTC00_RD_BUS_SAFETY_FI
0x187C8 MSS_CTRL_PERI_VBUSP_BUS_SAFETY_ERR
  fields as MSS_CTRL_TPTC00_RD_BUS_SAFETY_ERR
0x187CC MSS_CTRL_PERI_VBUSP_BUS_SAFETY_ERR_STAT_DATA0 16-bit
  fields as MSS_CTRL_TPTC00_RD_BUS_SAFETY_ERR_STAT_DATA0
0x187D0 MSS_CTRL_PERI_VBUSP_BUS_SAFETY_ERR_STAT_CMD
  fields as MSS_CTRL_TPTC00_RD_BUS_SAFETY_ERR_STAT_CMD
0x187D4 MSS_CTRL_PERI_VBUSP_BUS_SAFETY_ERR_STAT_WRITE
  fields as MSS_CTRL_TPTC00_RD_BUS_SAFETY_ERR_STAT_CMD
0x187D8 MSS_CTRL_PERI_VBUSP_BUS_SAFETY_ERR_STAT_READ
  fields as MSS_CTRL_TPTC00_RD_BUS_SAFETY_ERR_STAT_CMD
0x187DC MSS_CTRL_PERI_VBUSP_BUS_SAFETY_ERR_STAT_WRITERESP
  fields as MSS_CTRL_TPTC00_RD_BUS_SAFETY_ERR_STAT_CMD
0x18820 MSS_CTRL_NERROR_MASK 8-bit rw
  [2:0] MASK — writing 3'b111 will mask the Nerror propagation to padWriting 3'b000 will unmask the Nerror propagation to pad
0x18824 MSS_CTRL_MSS_BUS_SAFETY_SEC_ERR_STAT0
  [30] ICSSM_SLAVE — Bus safety single-bit-error of Node mentioned in the field
  [29] ICSSM_PDSP1 — Bus safety single-bit-error of Node mentioned in the field
  [28] ICSSM_PDSP0 — Bus safety single-bit-error of Node mentioned in the field
  [27] MSS_MBOX — Bus safety single-bit-error of Node mentioned in the field
  [n+23] L2RAM{n} (n=0..3) — Bus safety single-bit-error of Node mentioned in the field
  [22] SCRM2SCRP_1 — Bus safety single-bit-error of Node mentioned in the field
  [21] SCRM2SCRP_0 — Bus safety single-bit-error of Node mentioned in the field
  [20] DTHE — Bus safety single-bit-error of Node mentioned in the field
  [19] HSM_S — Bus safety single-bit-error of Node mentioned in the field
  [18] MCRC — Bus safety single-bit-error of Node mentioned in the field
  [17] QSPI — Bus safety single-bit-error of Node mentioned in the field
  [16] HSM_TPTC_A1_WR — Bus safety single-bit-error of Node mentioned in the field
  [15] HSM_TPTC_A1_RD — Bus safety single-bit-error of Node mentioned in the field
  [14] HSM_TPTC_A0_WR — Bus safety single-bit-error of Node mentioned in the field
  [13] HSM_TPTC_A0_RD — Bus safety single-bit-error of Node mentioned in the field
  [12] MSS_TPTC_A1_WR — Bus safety single-bit-error of Node mentioned in the field
  [11] MSS_TPTC_A0_WR — Bus safety single-bit-error of Node mentioned in the field
  [10] MSS_TPTC_A1_RD — Bus safety single-bit-error of Node mentioned in the field
  [9] MSS_TPTC_A0_RD — Bus safety single-bit-error of Node mentioned in the field
  [8] CPSW — Bus safety single-bit-error of Node mentioned in the field
  [7] HSM — Bus safety single-bit-error of Node mentioned in the field
  [6] DAP — Bus safety single-bit-error of Node mentioned in the field
  [5] CR5B_SLV — Bus safety single-bit-error of Node mentioned in the field
  [4] CR5A_SLV — Bus safety single-bit-error of Node mentioned in the field
  [3] CR5B_WR — Bus safety single-bit-error of Node mentioned in the field
  [2] CR5A_WR — Bus safety single-bit-error of Node mentioned in the field
  [1] CR5B_RD — Bus safety single-bit-error of Node mentioned in the field
  [0] CR5A_RD — Bus safety single-bit-error of Node mentioned in the field
0x18828 MSS_CTRL_MSS_BUS_SAFETY_SEC_ERR_STAT1
  [26] CR5A1_WR — Bus safety single-bit-error of Node mentioned in the field
  [25] CR5B1_RD — Bus safety single-bit-error of Node mentioned in the field
  [24] CR5A1_RD — Bus safety single-bit-error of Node mentioned in the field
  [5] GPMC — Bus safety single-bit-error of Node mentioned in the field
  [4] MMC — Bus safety single-bit-error of Node mentioned in the field
  [3] STM_STIM — Bus safety single-bit-error of Node mentioned in the field
  [2] CR5B1_SLV — Bus safety single-bit-error of Node mentioned in the field
  [1] CR5A1_SLV — Bus safety single-bit-error of Node mentioned in the field
  [0] CR5B1_WR — Bus safety single-bit-error of Node mentioned in the field
0x18834 MSS_CTRL_MSS_VBUSM_SAFETY_H_ERRAGG_MASK0 rw
  [31] DTHE_VBUSM_ERRH — Mask Error from MSS_VBUSM_SAFETY_H0_ERRAGG to aggregated Error MSS_VBUSM_SAFETY_H0_ERRAGG_ERRAGG1 : Error is Masked0 : Error is Unmasked
  [30] MCRC_VBUSM_ERRH — Mask Error from MSS_VBUSM_SAFETY_H0_ERRAGG to aggregated Error MSS_VBUSM_SAFETY_H0_ERRAGG_ERRAGG1 : Error is Masked0 : Error is Unmasked
  [29] QSPI_VBUSM_ERRH — Mask Error from MSS_VBUSM_SAFETY_H0_ERRAGG to aggregated Error MSS_VBUSM_SAFETY_H0_ERRAGG_ERRAGG1 : Error is Masked0 : Error is Unmasked
  [28] ICSSM_PDSP1_VBUSM_ERRH — Mask Error from MSS_VBUSM_SAFETY_H0_ERRAGG to aggregated Error MSS_VBUSM_SAFETY_H0_ERRAGG_ERRAGG1 : Error is Masked0 : Error is Unmasked
  [27] ICSSM_PDSP0_VBUSM_ERRH — Mask Error from MSS_VBUSM_SAFETY_H0_ERRAGG to aggregated Error MSS_VBUSM_SAFETY_H0_ERRAGG_ERRAGG1 : Error is Masked0 : Error is Unmasked
  [26] HSM_TPTC1_WR_VBUSM_ERRH — Mask Error from MSS_VBUSM_SAFETY_H0_ERRAGG to aggregated Error MSS_VBUSM_SAFETY_H0_ERRAGG_ERRAGG1 : Error is Masked0 : Error is Unmasked
  [25] HSM_TPTC1_RD_VBUSM_ERRH — Mask Error from MSS_VBUSM_SAFETY_H0_ERRAGG to aggregated Error MSS_VBUSM_SAFETY_H0_ERRAGG_ERRAGG1 : Error is Masked0 : Error is Unmasked
  [24] HSM_TPTC0_WR_VBUSM_ERRH — Mask Error from MSS_VBUSM_SAFETY_H0_ERRAGG to aggregated Error MSS_VBUSM_SAFETY_H0_ERRAGG_ERRAGG1 : Error is Masked0 : Error is Unmasked
  [23] HSM_TPTC0_RD_VBUSM_ERRH — Mask Error from MSS_VBUSM_SAFETY_H0_ERRAGG to aggregated Error MSS_VBUSM_SAFETY_H0_ERRAGG_ERRAGG1 : Error is Masked0 : Error is Unmasked
  [22] TPTC1_WR_VBUSM_ERRH — Mask Error from MSS_VBUSM_SAFETY_H0_ERRAGG to aggregated Error MSS_VBUSM_SAFETY_H0_ERRAGG_ERRAGG1 : Error is Masked0 : Error is Unmasked
  [21] TPTC0_WR_VBUSM_ERRH — Mask Error from MSS_VBUSM_SAFETY_H0_ERRAGG to aggregated Error MSS_VBUSM_SAFETY_H0_ERRAGG_ERRAGG1 : Error is Masked0 : Error is Unmasked
  [20] TPTC1_RD_VBUSM_ERRH — Mask Error from MSS_VBUSM_SAFETY_H0_ERRAGG to aggregated Error MSS_VBUSM_SAFETY_H0_ERRAGG_ERRAGG1 : Error is Masked0 : Error is Unmasked
  [19] TPTC0_RD_VBUSM_ERRH — Mask Error from MSS_VBUSM_SAFETY_H0_ERRAGG to aggregated Error MSS_VBUSM_SAFETY_H0_ERRAGG_ERRAGG1 : Error is Masked0 : Error is Unmasked
  [n+15] L2RAM{n}_VBUSM_ERRH (n=0..3) — Mask Error from MSS_VBUSM_SAFETY_H0_ERRAGG to aggregated Error MSS_VBUSM_SAFETY_H0_ERRAGG_ERRAGG1 : Error is Masked0 : Error is Unmasked
  [14] CPSW_VBUSM_ERRH — Mask Error from MSS_VBUSM_SAFETY_H0_ERRAGG to aggregated Error MSS_VBUSM_SAFETY_H0_ERRAGG_ERRAGG1 : Error is Masked0 : Error is Unmasked
  [13] HSM_VBUSM_ERRH — Mask Error from MSS_VBUSM_SAFETY_H0_ERRAGG to aggregated Error MSS_VBUSM_SAFETY_H0_ERRAGG_ERRAGG1 : Error is Masked0 : Error is Unmasked
  [12] DAP_VBUSM_ERRH — Mask Error from MSS_VBUSM_SAFETY_H0_ERRAGG to aggregated Error MSS_VBUSM_SAFETY_H0_ERRAGG_ERRAGG1 : Error is Masked0 : Error is Unmasked
  [11] CR5B1_SLV_VBUSM_ERRH — Mask Error from MSS_VBUSM_SAFETY_H0_ERRAGG to aggregated Error MSS_VBUSM_SAFETY_H0_ERRAGG_ERRAGG1 : Error is Masked0 : Error is Unmasked
  [10] CR5A1_SLV_VBUSM_ERRH — Mask Error from MSS_VBUSM_SAFETY_H0_ERRAGG to aggregated Error MSS_VBUSM_SAFETY_H0_ERRAGG_ERRAGG1 : Error is Masked0 : Error is Unmasked
  [9] CR5B1_WR_VBUSM_ERRH — Mask Error from MSS_VBUSM_SAFETY_H0_ERRAGG to aggregated Error MSS_VBUSM_SAFETY_H0_ERRAGG_ERRAGG1 : Error is Masked0 : Error is Unmasked
  [8] CR5A1_WR_VBUSM_ERRH — Mask Error from MSS_VBUSM_SAFETY_H0_ERRAGG to aggregated Error MSS_VBUSM_SAFETY_H0_ERRAGG_ERRAGG1 : Error is Masked0 : Error is Unmasked
  [7] CR5B1_RD_VBUSM_ERRH — Mask Error from MSS_VBUSM_SAFETY_H0_ERRAGG to aggregated Error MSS_VBUSM_SAFETY_H0_ERRAGG_ERRAGG1 : Error is Masked0 : Error is Unmasked
  [6] CR5A1_RD_VBUSM_ERRH — Mask Error from MSS_VBUSM_SAFETY_H0_ERRAGG to aggregated Error MSS_VBUSM_SAFETY_H0_ERRAGG_ERRAGG1 : Error is Masked0 : Error is Unmasked
  [5] CR5B0_SLV_VBUSM_ERRH — Mask Error from MSS_VBUSM_SAFETY_H0_ERRAGG to aggregated Error MSS_VBUSM_SAFETY_H0_ERRAGG_ERRAGG1 : Error is Masked0 : Error is Unmasked
  [4] CR5A0_SLV_VBUSM_ERRH — Mask Error from MSS_VBUSM_SAFETY_H0_ERRAGG to aggregated Error MSS_VBUSM_SAFETY_H0_ERRAGG_ERRAGG1 : Error is Masked0 : Error is Unmasked
  [3] CR5B0_WR_VBUSM_ERRH — Mask Error from MSS_VBUSM_SAFETY_H0_ERRAGG to aggregated Error MSS_VBUSM_SAFETY_H0_ERRAGG_ERRAGG1 : Error is Masked0 : Error is Unmasked
  [2] CR5A0_WR_VBUSM_ERRH — Mask Error from MSS_VBUSM_SAFETY_H0_ERRAGG to aggregated Error MSS_VBUSM_SAFETY_H0_ERRAGG_ERRAGG1 : Error is Masked0 : Error is Unmasked
  [1] CR5B0_RD_VBUSM_ERRH — Mask Error from MSS_VBUSM_SAFETY_H0_ERRAGG to aggregated Error MSS_VBUSM_SAFETY_H0_ERRAGG_ERRAGG1 : Error is Masked0 : Error is Unmasked
  [0] CR5A0_RD_VBUSM_ERRH — Mask Error from MSS_VBUSM_SAFETY_H0_ERRAGG to aggregated Error MSS_VBUSM_SAFETY_H0_ERRAGG_ERRAGG1 : Error is Masked0 : Error is Unmasked
